# PWMSS_ECAP register map
Vendor: Texas Instruments
Peripheral module from a debugger description file (folder am437x).
Registers are 32-bit, read-write, no defined reset value unless marked. A register's access mark holds for its fields unless they carry their own. Offsets are as the file gives them; lines under a group give offsets from that group; [hi:lo] are bit positions; {n}, {i} and the like mark numbered series; 'fields as' and 'values as' point back to an identical list; <NAME> marks a mode.

## PWMSS_ECAP
0x00 TSCTR
  [31:0] TSCTR — Active 32 bit counter register that is used as the capture time-base
0x04 CTRPHS
  [31:0] CTRPHS — Counter phase value register that can be programmed for phase lag/lead. [[br]]This register shadows TSCTR and is loaded into TSCTR upon either a SYNCI event or S/W force via a control bit. [[br]]Used to achieve phase control synchronization with respect to other eCAP and EPWM time-bases.
0x08 CAP1
  [31:0] CAP1 — This register can be loaded (written) by the following. [[br]](a) Time-Stamp (that is, counter value) during a capture event. [[br]](b) Software may be useful for test purposes. [[br]](c) APRD active register when used in APWM mode.
0x0C CAP2
  [31:0] CAP2 — This register can be loaded (written) by the following. [[br]](a) Time-Stamp (that is, counter value) during a capture event. [[br]](b) Software may be useful for test purposes. [[br]](c) APRD active register when used in APWM mode.
0x10 CAP3
  [31:0] CAP3 — In CMP mode, this is a time-stamp capture register. [[br]]In APWM mode, this is the period shadow (APRD) register. [[br]]You update the PWM period value through this register. [[br]]In this mode, CAP3 shadows CAP1.
0x14 CAP4
  [31:0] CAP4 — In CMP mode, this is a time-stamp capture register. [[br]]In APWM mode, this is the compare shadow (ACMP) register. [[br]]You update the PWM compare value through this register. [[br]]In this mode, CAP4 shadows CAP2.
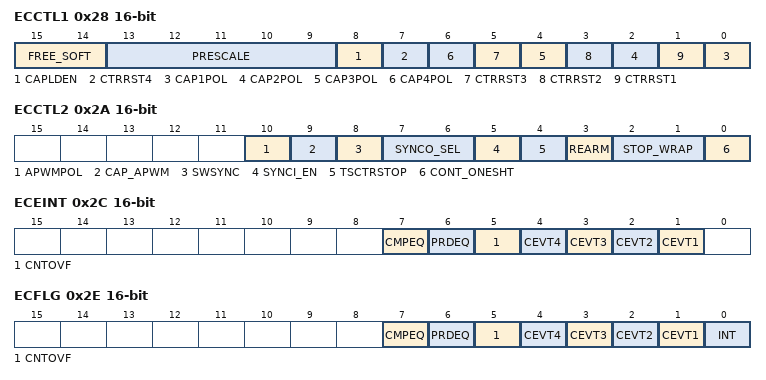
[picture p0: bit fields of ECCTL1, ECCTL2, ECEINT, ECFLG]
0x28 ECCTL1 16-bit
  [15:14] FREE_SOFT — Emulation Control
    3=en_4_0x3 (TSCTR counter is unaffected by emulation suspend (Run Free).); 2=en_3_0x2 (TSCTR counter is unaffected by emulation suspend (Run Free).); 1=en_2_0x1 (TSCTR counter runs until = 0.); 0=en_1_0x0 (TSCTR counter stops immediately on emulation suspend.)
  [13:9] PRESCALE — Event Filter prescale select ...
    31=en_8_0x1F (Divide by 62); 30=en_7_0x1E (Divide by 60); 5=en_6_0x5 (Divide by 10); 4=en_5_0x4 (Divide by 8); 3=en_4_0x3 (Divide by 6); 2=en_3_0x2 (Divide by 4); 1=en_2_0x1 (Divide by 2); 0=en_1_0x0 (Divide by 1 (i.e,. no prescale, by-pass the prescaler))
  [8] CAPLDEN — Enable Loading of CAP1 to CAP4 registers on a capture event
    1=en_2_0x1 (Enable CAP1-4 register loads at capture event time.); 0=en_1_0x0 (Disable CAP1 through 4 register loads at capture event time.)
  [7] CTRRST4 — Counter Reset on Capture Event 4
    1=en_2_0x1 (Reset counter after Capture Event 4 time-stamp has been captured (used in difference mode operation)); 0=en_1_0x0 (Do not reset counter on Capture Event 4 (absolute time stamp operation))
  [2n-2] CAP{n}POL (n=1..4) — Capture Event {n} Polarity select
    1=en_2_0x1 (Capture Event {n} triggered on a falling edge (FE)); 0=en_1_0x0 (Capture Event {n} triggered on a rising edge (RE))
  [5] CTRRST3 — Counter Reset on Capture Event 3
    1=en_2_0x1 (Reset counter after Event 3 time-stamp has been captured (used in difference mode operation)); 0=en_1_0x0 (Do not reset counter on Capture Event 3 (absolute time stamp))
  [3] CTRRST2 — Counter Reset on Capture Event 2
    1=en_2_0x1 (Reset counter after Event 2 time-stamp has been captured (used in difference mode operation)); 0=en_1_0x0 (Do not reset counter on Capture Event 2 (absolute time stamp))
  [1] CTRRST1 — Counter Reset on Capture Event 1
    1=en_2_0x1 (Reset counter after Event 1 time-stamp has been captured (used in difference mode operation)); 0=en_1_0x0 (Do not reset counter on Capture Event 1 (absolute time stamp))
0x2A ECCTL2 16-bit access per field
  [10] APWMPOL rw — APWM output polarity select. [[br]]This is applicable only in APWM operating mode
    1=en_2_0x1 (Output is active low (Compare value defines low time)); 0=en_1_0x0 (Output is active high (Compare value defines high time))
  [9] CAP_APWM rw — CAP/APWM operating mode select
    1=en_2_0x1 (ECAP module operates in APWM mode. This mode forces the following configuration. (a) Resets TSCTR on PRDEQ event (period boundary). (b) Permits shadow loading on CAP1 and 2 registers. (c) Disables loading of time-stamps into CAP1-4 registers. (d) ECAPn/APWMn pin operates as a APWM output.); 0=en_1_0x0 (ECAP module operates in capture mode. This mode forces the following configuration. (a) Inhibits TSCTR resets via PRDEQ event. (b) Inhibits shadow loads on CAP1 and 2 registers. (c) Permits user to enable CAP1-4 register load. (d) ECAPn/APWMn pin operates as a capture input.)
  [8] SWSYNC rw — Software-forced Counter (TSCTR) Synchronizing. [[br]]This provides a convenient software method to synchronize some or all ECAP time bases. [[br]]In APWM mode, the synchronizing can also be done via the PRDEQ event. [[br]]Note: Selecting PRDEQ is meaningful only in APWM mode. [[br]]However, you can choose it in CAP mode if you find doing so useful.
    1=en_2_0x1 (Writing a one forces a TSCTR shadow load of current ECAP module and any ECAP modules down-stream providing the SYNCO_SEL bits are 0,0. After writing a 1, this bit returns to a zero.); 0=en_1_0x0 (Writing a zero has no effect. Reading always returns a zero)
  [7:6] SYNCO_SEL rw — Sync-Out Select
    3=en_4_0x3 (Disable sync out signal); 2=en_3_0x2 (Disable sync out signal); 1=en_2_0x1 (Select PRDEQ event to be the sync-out signal); 0=en_1_0x0 (Select sync-in event to be the sync-out signal (pass through))
  [5] SYNCI_EN rw — Counter (TSCTR) Sync-In select mode
    1=en_2_0x1 (Enable counter (TSCTR) to be loaded from CTRPHS register upon either a SYNCI signal or a S/W force event.); 0=en_1_0x0 (Disable sync-in option)
  [4] TSCTRSTOP rw — Time Stamp (TSCTR) Counter Stop (freeze) Control
    1=en_2_0x1 (TSCTR free-running); 0=en_1_0x0 (TSCTR stopped)
  [3] REARM rw — One-Shot Re-Arming Control, that is, wait for stop trigger. [[br]]Note: The re-arm function is valid in one shot or continuous mode.
    1=en_2_0x1 (Arms the one-shot sequence as follows: 1) Resets the Mod4 counter to zero. 2) Unfreezes the Mod4 counter. 3) Enables capture register loads.); 0=en_1_0x0 (Has no effect (reading always returns a 0))
  [2:1] STOP_WRAP rw — Stop value for one-shot mode. [[br]]This is the number (between 1 and 4) of captures allowed to occur before the CAP (1 through 4) registers are frozen, that is, capture sequence is stopped. [[br]]Wrap value for continuous mode. [[br]]This is the number (between 1 and 4) of the capture register in which the circular buffer wraps around and starts again. [[br]]Notes: STOP_WRAP is compared to Mod4 counter and, when equal, the following two actions occur. [[br]](1) Mod4 counter is stopped (frozen), and (2) Capture register loads are inhibited. [[br]]In one-shot mode, further interrupt events are blocked until re-armed.
    {v}=en_{v+1}_{0x0+v} (Stop after Capture Event {v+1} in one-shot mode. Wrap after Capture Event {v+1} in continuous mode.) (v=0..3)
  [0] CONT_ONESHT rw — Continuous or one-shot mode control (applicable only in capture mode)
    1=en_2_0x1 (Operate in one-shot mode); 0=en_1_0x0 (Operate in continuous mode)
0x2C ECEINT 16-bit access per field — The interrupt enable bits (CEVTn) block any of the selected events from generating an interrupt. Events will still be latched into the flag bit (ECFLG register) and can be forced or cleared via the ECFRC and ECCLR registers. The proper procedure for configuring peripheral modes and interrupts is: 1. Disable global interrupts. 2. Stop eCAP counter. 3. Disable eCAP interrupts. 4. Configure peripheral registers. 5. Clear spurious eCAP interrupt flags. 6. Enable eCAP interrupts. 7. Start eCAP counter. 8. Enable global interrupts.
  [7] CMPEQ rw — Counter Equal Compare Interrupt Enable.
    1=en_2_0x1 (Enable Compare Equal as an Interrupt source.); 0=en_1_0x0 (Disable Compare Equal as an Interrupt source.)
  [6] PRDEQ rw — Counter Equal Period Interrupt Enable.
    1=en_2_0x1 (Enable Period Equal as an Interrupt source.); 0=en_1_0x0 (Disable Period Equal as an Interrupt source.)
  [5] CNTOVF rw — Counter Overflow Interrupt Enable.
    1=en_2_0x1 (Enable counter Overflow as an Interrupt source.); 0=en_1_0x0 (Disable counter Overflow as an Interrupt source.)
  [4] CEVT4 rw — Capture Event 4 Interrupt Enable.
    1=en_2_0x1 (Enable Capture Event 4 as an Interrupt source.); 0=en_1_0x0 (Disable Capture Event 4 as an Interrupt source.)
  [3] CEVT3 rw — Capture Event 3 Interrupt Enable.
    1=en_2_0x1 (Enable Capture Event 3 as an Interrupt source.); 0=en_1_0x0 (Disable Capture Event 3 as an Interrupt source.)
  [2] CEVT2 rw — Capture Event 2 Interrupt Enable.
    1=en_2_0x1 (Enable Capture Event 2 as an Interrupt source.); 0=en_1_0x0 (Disable Capture Event 2 as an Interrupt source.)
  [1] CEVT1 rw — Capture Event 1 Interrupt Enable .
    1=en_2_0x1 (Enable Capture Event 1 as an Interrupt source.); 0=en_1_0x0 (Disable Capture Event 1 as an Interrupt source.)
0x2E ECFLG 16-bit ro
  [7] CMPEQ — Compare Equal Compare Status Flag. [[br]]This flag is only active in APWM mode.
    1=en_2_0x1 (Indicates the counter (TSCTR) reached the compare register value (ACMP)); 0=en_1_0x0 (Indicates no event occurred)
  [6] PRDEQ — Counter Equal Period Status Flag. [[br]]This flag is only active in APWM mode.
    1=en_2_0x1 (Indicates the counter (TSCTR) reached the period register value (APRD) and was reset.); 0=en_1_0x0 (Indicates no event occurred)
  [5] CNTOVF — Counter Overflow Status Flag. [[br]]This flag is active in CAP and APWM mode.
    1=en_2_0x1 (Indicates the counter (TSCTR) has made the transition from 0xFFFFFFFF to 0x00000000); 0=en_1_0x0 (Indicates no event occurred.)
  [4] CEVT4 — Capture Event 4 Status Flag This flag is only active in CAP mode.
    1=en_2_0x1 (Indicates the fourth event occurred at ECAPn pin); 0=en_1_0x0 (Indicates no event occurred)
  [3] CEVT3 — Capture Event 3 Status Flag. [[br]]This flag is active only in CAP mode.
    1=en_2_0x1 (Indicates the third event occurred at ECAPn pin.); 0=en_1_0x0 (Indicates no event occurred.)
  [2] CEVT2 — Capture Event 2 Status Flag. [[br]]This flag is only active in CAP mode.
    1=en_2_0x1 (Indicates the second event occurred at ECAPn pin.); 0=en_1_0x0 (Indicates no event occurred.)
  [1] CEVT1 — Capture Event 1 Status Flag. [[br]]This flag is only active in CAP mode.
    1=en_2_0x1 (Indicates the first event occurred at ECAPn pin.); 0=en_1_0x0 (Indicates no event occurred.)
  [0] INT — Global Interrupt Status Flag
    1=en_2_0x1 (Indicates that an interrupt was generated.); 0=en_1_0x0 (Indicates no interrupt generated.)
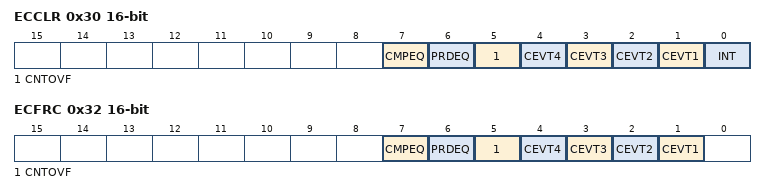
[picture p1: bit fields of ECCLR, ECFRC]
0x30 ECCLR 16-bit access per field
  [7] CMPEQ rw — Counter Equal Compare Status Flag
    1=en_2_0x1 (Writing a 1 clears the CMPEQ flag condition); 0=en_1_0x0 (Writing a 0 has no effect. Always reads back a 0)
  [6] PRDEQ rw — Counter Equal Period Status Flag
    1=en_2_0x1 (Writing a 1 clears the PRDEQ flag condition); 0=en_1_0x0 (Writing a 0 has no effect. Always reads back a 0)
  [5] CNTOVF rw — Counter Overflow Status Flag
    1=en_2_0x1 (Writing a 1 clears the CNTOVF flag condition); 0=en_1_0x0 (Writing a 0 has no effect. Always reads back a 0)
  [4] CEVT4 rw — Capture Event 4 Status Flag
    1=en_2_0x1 (Writing a 1 clears the CEVT3 flag condition.); 0=en_1_0x0 (Writing a 0 has no effect. Always reads back a 0.)
  [3] CEVT3 rw — Capture Event 3 Status Flag
    values as CEVT4
  [2] CEVT2 rw — Capture Event 2 Status Flag
    1=en_2_0x1 (Writing a 1 clears the CEVT2 flag condition.); 0=en_1_0x0 (Writing a 0 has no effect. Always reads back a 0.)
  [1] CEVT1 rw — Capture Event 1 Status Flag
    1=en_2_0x1 (Writing a 1 clears the CEVT1 flag condition.); 0=en_1_0x0 (Writing a 0 has no effect. Always reads back a 0.)
  [0] INT rw — Global Interrupt Clear Flag
    1=en_2_0x1 (Writing a 1 clears the INT flag and enable further interrupts to be generated if any of the event flags are set to 1.); 0=en_1_0x0 (Writing a 0 has no effect. Always reads back a 0.)
0x32 ECFRC 16-bit access per field
  [7] CMPEQ rw — Force Counter Equal Compare Interrupt
    1=en_2_0x1 (Writing a 1 sets the CMPEQ flag bit.); 0=en_1_0x0 (No effect. Always reads back a 0.)
  [6] PRDEQ rw — Force Counter Equal Period Interrupt
    1=en_2_0x1 (Writing a 1 sets the PRDEQ flag bit.); 0=en_1_0x0 (No effect. Always reads back a 0.)
  [5] CNTOVF rw — Force Counter Overflow
    1=en_2_0x1 (Writing a 1 to this bit sets the CNTOVF flag bit.); 0=en_1_0x0 (No effect. Always reads back a 0.)
  [4] CEVT4 rw — Force Capture Event 4
    1=en_2_0x1 (Writing a 1 sets the CEVT4 flag bit); 0=en_1_0x0 (No effect. Always reads back a 0.)
  [3] CEVT3 rw — Force Capture Event 3
    1=en_2_0x1 (Writing a 1 sets the CEVT3 flag bit); 0=en_1_0x0 (No effect. Always reads back a 0.)
  [2] CEVT2 rw — Force Capture Event 2
    1=en_2_0x1 (Writing a 1 sets the CEVT2 flag bit.); 0=en_1_0x0 (No effect. Always reads back a 0.)
  [1] CEVT1 rw — Always reads back a 0. [[br]]Force Capture Event 1
    1=en_2_0x1 (Writing a 1 sets the CEVT1 flag bit.); 0=en_1_0x0 (No effect.)
0x5C REVID ro
  [31:0] REV — Revision ID.
